AUTOSAR XML (schema 3.2.3)
standard types defined: Boolean
package /DataTypes
  integer type Movement: compu {phys=raw*2.5+10 for raw 0..3}, lower-limit=0, upper-limit=3
  integer type Position: compu {0=STANDARD_POSITION (StandardPosition), 1=FORWARD_POSITION (ForwardPosition), 2=BACKWARD_POSITION (BackwardPosition)}, lower-limit=0, upper-limit=7
package /Constants
  4 x constant specification:
    BooleanFalse
      value:
        boolean literal literal: type=Boolean, value=false
    BooleanTrue
      value:
        boolean literal literal: type=Boolean, value=true
    MovementStop
      value:
        integer literal literal: type=Movement, value=0
    PositionStandard
      value:
        integer literal literal: type=Position, value=0
package /Network/CanCluster
  can cluster Network: max-frame-length=8, protocol-name=CAN, protocol-version=can2.0b, speed=250000
    physical channel Network
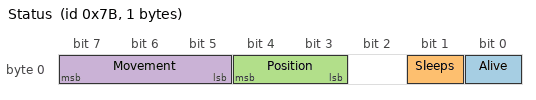
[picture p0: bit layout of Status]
      frame Status: id 0x7B, frame-length=1, can-addressing-mode=STANDARD  # The lonely frame description
        pdu Status: length=1, cyclic-timing=repeating-time=0.5, event-controlled-timing=number-of-repeats=0, minimum-delay=0.01
          signal Alive: start 0, 1 bit, little-endian, data-type=Boolean, init-value=BooleanFalse/literal  # Lebt! / Is alive!  # Lebt / Is alive
          signal Sleeps: start 1, 1 bit, little-endian, system signal IsAsleep, data-type=Boolean, init-value=BooleanTrue/literal
          signal Position: start 3, 2 bit, little-endian, data-type=Position, init-value=PositionStandard/literal
          signal Movement: start 5, 3 bit, little-endian, data-type=Movement, init-value=MovementStop/literal  # Lonely system signal comment
          signal PositionMovement: little-endian, system signal PositionMovementGroup, system-signal=[Movement, Position]
